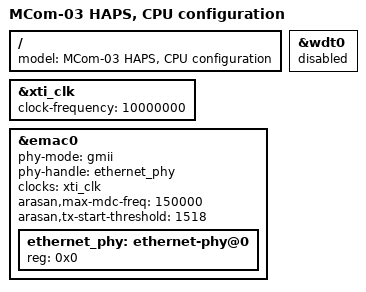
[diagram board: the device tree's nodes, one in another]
// SPDX-License-Identifier: GPL-2.0+
/*
 * Copyright 2020 RnD Center "ELVEES", JSC
 */

/dts-v1/;

#include "mcom03-haps-common.dtsi"

/ {
	model = "MCom-03 HAPS, CPU configuration";
};

&xti_clk {
	clock-frequency = <10000000>;
};

&emac0 {
	#address-cells = <1>;
	#size-cells = <0>;
	phy-mode = "gmii";
	status = "okay";
	phy-handle = <&ethernet_phy>;
	clocks = <&xti_clk>;

	/* These two are required on HAPS due to its low frequency  */
	arasan,max-mdc-freq = <150000>;
	arasan,tx-start-threshold = <1518>;

	ethernet_phy: ethernet-phy@0 {
		reg = <0x0>;
	};
};

&wdt0 {
	status = "disabled";
};
